# ATxmega128B3 device description
Architecture: AVR8_XMEGA; Family: AVR XMEGA
Registers are 8-bit, access not given, no defined reset value unless marked. A register's access mark holds for its fields unless they carry their own. Offsets are from the block's base; [hi:lo] are bit positions; {n}, {i} and the like mark numbered series; 'fields as' and 'values as' point back to an identical list.

## IRCOM — IR Communication Module
Instances: IRCOM 0x8F8
0x00 CTRL — Control Register
  [3:0] EVSEL — Event Channel Select
    0=OFF (No Event Source); {v}=Event Channel {v-8} (v=8..11)
0x01 TXPLCTRL — IrDA Transmitter Pulse Length Control Register
0x02 RXPLCTRL — IrDA Receiver Pulse Length Control Register

## LCD — LCD Controller
Instances: LCD 0x0D00
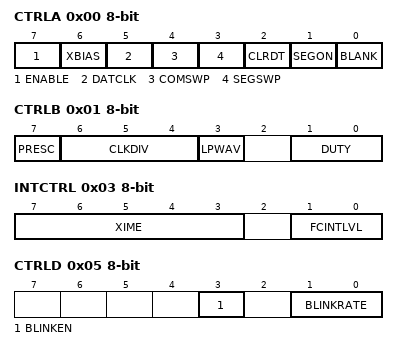
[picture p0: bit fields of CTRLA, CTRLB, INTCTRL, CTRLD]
0x00 CTRLA — Control Register A
  [7] ENABLE — LCD Enable
  [6] XBIAS — External Register Bias Generation
  [5] DATCLK — Data Register Lock
  [4] COMSWP — Common Bus Swap
  [3] SEGSWP — Segment Bus Swap
  [2] CLRDT — Clear Data Register
  [1] SEGON — Segments On
  [0] BLANK — Blanking Display Mode
0x01 CTRLB — Control Register B
  [7] PRESC — LCD Prescaler Select
    0=clk_lcd/8; 1=clk_lcd/16
  [6:4] CLKDIV — LCD Clock Divide
    0=DivBy1 (frame rate of 256 Hz); 1=DivBy2 (frame rate of 128 Hz); 2=DivBy3 (frame rate of 83.5 Hz); 3=DivBy4 (frame rate of 64 Hz); 4=DivBy5 (frame rate of 51.2 Hz); 5=DivBy6 (frame rate of 42.7 Hz); 6=DivBy7 (frame rate of 36.6 Hz); 7=DivBy8 (frame rate of 32 Hz)
  [3] LPWAV — Low Power Waveform
  [1:0] DUTY — Duty Select
    0=1_4 (Duty=1/4, Bias=1/3, COM0:3); 1=Static (Duty=Static, Bias=Static, COM0); 2=1_2 (Duty=1/2, Bias=1/3, COM0:1); 3=1_3 (Duty=1/3, Bias=1/3, COM0:2)
0x02 CTRLC — Control Register C
  [5:0] PMSK — LCD Port Mask
0x03 INTCTRL — Interrupt Enable Register
  [7:3] XIME — eXtended Interrupt Mode Enable
  [1:0] FCINTLVL — Interrupt Level
    0=OFF (Interrupt disabled); 1=LO (Low level); 2=MED (Medium level); 3=HI (High level)
0x04 INTFLAG — Interrupt Flag Register
  [0] FCIF — LCD Frame Completed Interrupt Flag
0x05 CTRLD — Control Register D
  [3] BLINKEN — Blink Enable
  [1:0] BLINKRATE — LCD Blink Rate
    0=4Hz (4Hz Blink Rate); 1=2Hz (2Hz Blink Rate); 2=1Hz (1Hz Blink Rate); 3=0Hz5 (0.5Hz Blink Rate)
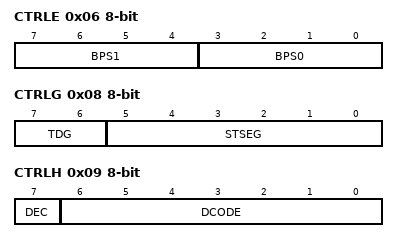
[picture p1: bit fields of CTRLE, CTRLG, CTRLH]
0x06 CTRLE — Control Register E
  [7:4] BPS1 — Blink Pixel Selection 1
  [3:0] BPS0 — Blink Pixel Selection 0
0x07 CTRLF — Control Register F
  [5:0] FCONT — Fine Contrast
0x08 CTRLG — Control Register G
  [7:6] TDG — Type of Digit
    0=7S_3C (7-segment with 3 COMs); 1=7S_4C (7-segment with 4 COMs); 2=14S_4C (14-segment with 4 COMs); 3=16S_3C (16-segment with 3 COMs)
  [5:0] STSEG — Start Segment
0x09 CTRLH — Control Register H
  [7] DEC — Decrement of Start Segment
  [6:0] DCODE — Display Code
{0x10+i} DATA{i} (i=0..19) — LCD Data Register {i}

## NVM_FUSES — Fuses
Instances: FUSE 0x00 in fuses
0x00 FUSEBYTE0 reset 0xFF — JTAG User ID
  [7:0] JTAGUSERID
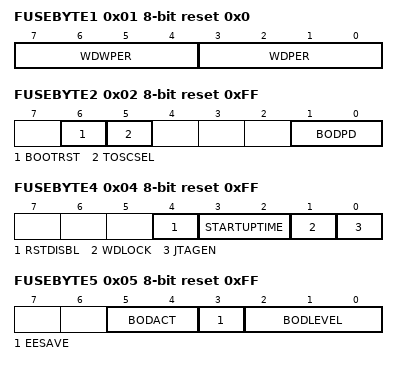
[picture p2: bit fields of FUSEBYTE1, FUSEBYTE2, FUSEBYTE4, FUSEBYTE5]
0x01 FUSEBYTE1 reset 0x0 — Watchdog Configuration
  [7:4] WDWPER — Watchdog Window Timeout Period
    0=8CLK (8 cycles (8ms @ 3.3V)); 1=16CLK (16 cycles (16ms @ 3.3V)); 2=32CLK (32 cycles (32ms @ 3.3V)); 3=64CLK (64 cycles (64ms @ 3.3V)); 4=128CLK (128 cycles (0.125s @ 3.3V)); 5=256CLK (256 cycles (0.25s @ 3.3V)); 6=512CLK (512 cycles (0.5s @ 3.3V)); 7=1KCLK (1K cycles (1s @ 3.3V)); 8=2KCLK (2K cycles (2s @ 3.3V)); 9=4KCLK (4K cycles (4s @ 3.3V)); 10=8KCLK (8K cycles (8s @ 3.3V))
  [3:0] WDPER — Watchdog Timeout Period
    values as WDWPER
0x02 FUSEBYTE2 reset 0xFF — Reset Configuration
  [6] BOOTRST — Boot Loader Section Reset Vector
    0=BOOTLDR (Boot Loader Reset); 1=APPLICATION (Application Reset)
  [5] TOSCSEL — Timer Oscillator pin location
    0=ALTERNATE (TOSC1 / TOSC2 on separate pins); 1=XTAL (TOSC1 / TOSC2 shared with XTAL1 / XTAL2)
  [1:0] BODPD — BOD Operation in Power-Down Mode
    1=SAMPLED (BOD enabled in sampled mode); 2=CONTINUOUS (BOD enabled continuously); 3=DISABLED (BOD Disabled)
0x04 FUSEBYTE4 reset 0xFF — Start-up Configuration
  [4] RSTDISBL — External Reset Disable
  [3:2] STARTUPTIME
    3=0MS; 1=4MS; 0=64MS
  [1] WDLOCK — Watchdog Timer Lock
  [0] JTAGEN — JTAG Interface Enable
0x05 FUSEBYTE5 reset 0xFF — EESAVE and BOD Level
  [5:4] BODACT — BOD Operation in Active Mode
    values as FUSEBYTE2.BODPD
  [3] EESAVE — Preserve EEPROM Through Chip Erase
  [2:0] BODLEVEL — Brownout Detection Voltage Level
    7=1V6 (1.6 V); 6=1V8 (1.8 V); 5=2V0 (2.0 V); 4=2V2 (2.2 V); 3=2V4 (2.4 V); 2=2V6 (2.6 V); 1=2V8 (2.8 V); 0=3V0 (3.0 V)

## NVM_LOCKBITS — Lock Bits
Instances: LOCKBIT 0x00 in lockbits
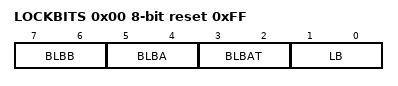
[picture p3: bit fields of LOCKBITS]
0x00 LOCKBITS reset 0xFF
  [7:6] BLBB — Boot Lock Bits - Boot Section
    0=RWLOCK (Read and write not allowed); 1=RLOCK (Read not allowed); 2=WLOCK (Write not allowed); 3=NOLOCK (No locks)
  [5:4] BLBA — Boot Lock Bits - Application Section
    values as BLBB
  [3:2] BLBAT — Boot Lock Bits - Application Table
    values as BLBB
  [1:0] LB — Lock Bits
    0=RWLOCK (Read and write not allowed); 2=WLOCK (Write not allowed); 3=NOLOCK (No locks)

## NVM_PROD_SIGNATURES (SIGROW module) — Production Signatures
Instances: PROD_SIGNATURES 0x00 in prod_signatures
0x00 RCOSC2M — RCOSC 2 MHz Calibration Value B
0x01 RCOSC2MA — RCOSC 2 MHz Calibration Value A
0x02 RCOSC32K — RCOSC 32.768 kHz Calibration Value
0x03 RCOSC32M — RCOSC 32 MHz Calibration Value B
0x04 RCOSC32MA — RCOSC 32 MHz Calibration Value A
{0x8+i} LOTNUM{i} (i=0..5) — Lot Number Byte {i}, ASCII
0x10 WAFNUM — Wafer Number
0x12 COORDX0 — Wafer Coordinate X Byte 0
0x13 COORDX1 — Wafer Coordinate X Byte 1
0x14 COORDY0 — Wafer Coordinate Y Byte 0
0x15 COORDY1 — Wafer Coordinate Y Byte 1
0x1A USBCAL0 — USB Calibration Byte 0
0x1B USBCAL1 — USB Calibration Byte 1
0x1C USBRCOSC — USB RCOSC Calibration Value B
0x1D USBRCOSCA — USB RCOSC Calibration Value A
0x20 ADCACAL0 — ADCA Calibration Byte 0
0x21 ADCACAL1 — ADCA Calibration Byte 1
0x24 ADCBCAL0 — ADCB Calibration Byte 0
0x25 ADCBCAL1 — ADCB Calibration Byte 1
0x2E TEMPSENSE0 — Temperature Sensor Calibration Byte 0
0x2F TEMPSENSE1 — Temperature Sensor Calibration Byte 1
